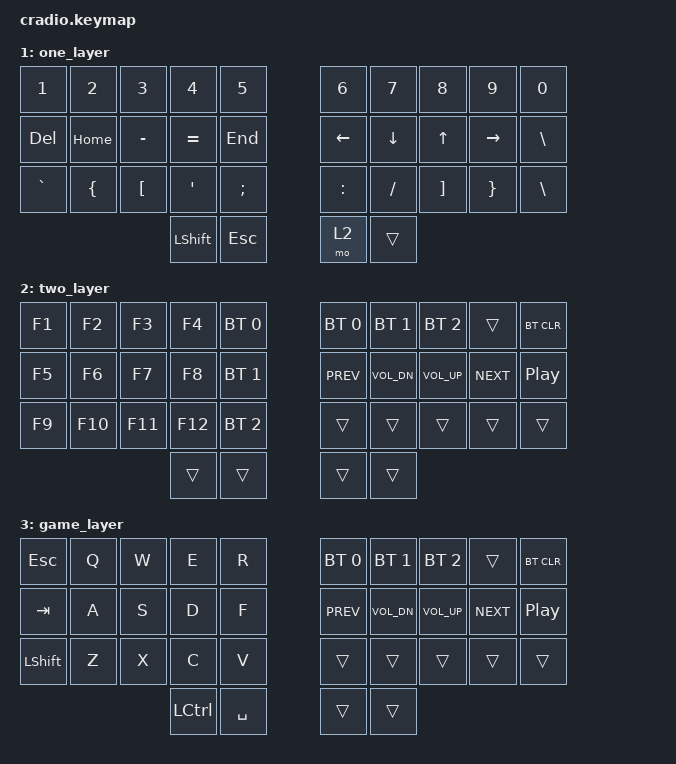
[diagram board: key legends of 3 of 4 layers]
// Copyright (c) 2022 The ZMK Contributors
// SPDX-License-Identifier: MIT

#include <behaviors.dtsi>
#include <dt-bindings/zmk/keys.h>
#include <dt-bindings/zmk/bt.h>

// Home row mods macro
#define HRML(k1,k2,k3) &ht LALT k1  &ht LCTRL k2  &ht LGUI k3
#define HRMR(k1,k2,k3) &ht RGUI k1  &ht RCTRL k2  &ht RALT k3
#define COMBO 60

/ {
    behaviors {
        ht: hold_tap {
            label = "hold_tap";
            compatible = "zmk,behavior-hold-tap";
            #binding-cells = <2>;
            flavor = "tap-preferred";
            tapping-term-ms = <220>;
            quick-tap-ms = <150>;
            require-prior-idle-ms = <100>;
            bindings = <&kp>, <&kp>;
        };
    };

    conditional_layers {
        compatible = "zmk,conditional-layers";
        tri_layer {
            if-layers = <1 2>;
            then-layer = <3>;
        };
    };
    combos {
        compatible = "zmk,combos";

        combo_del {
            timeout-ms = <COMBO>;
            key-positions = <17 18>;
            bindings = <&kp DEL>;
        };
        combo_bs_word{
            timeout-ms = <COMBO>;
            key-positions = <18 16 17>;
            bindings = <&kp LA(BSPC)>;
        };
        combo_bs{
            timeout-ms = <COMBO>;
            key-positions = <17 16>;
            bindings = <&kp BSPC>;
        };
        combo_esc {
            timeout-ms = <COMBO>;
            key-positions = <9 19>;
            bindings = <&kp ESC>;
        };

        combo_tab {
            timeout-ms = <COMBO>;
            key-positions = <12 13>;
            bindings = <&kp TAB>;
        };

        combo_lpar {
            timeout-ms = <COMBO>;
            key-positions = <2 12>;
            bindings = <&kp LPAR>;
        };
        combo_rpar {
            timeout-ms = <COMBO>;
            key-positions = <7 17>;
            bindings = <&kp RPAR>;
        };

        combo_lbkt {
            timeout-ms = <COMBO>;
            key-positions = <12 22>;
            bindings = <&kp LBKT>;
        };
        combo_rbkt {
            timeout-ms = <COMBO>;
            key-positions = <17 27>;
            bindings = <&kp RBKT>;
        };

    };
    
    keymap {
        compatible = "zmk,keymap";
        default_layer {
            bindings = <
        //╭──────────┬──────────┬──────────┬──────────┬──────────╮   ╭──────────┬──────────┬──────────┬──────────┬──────────╮
            &kp Q      &kp W      &kp E      &kp R      &kp T          &kp Y      &kp U      &kp I      &kp O      &kp P
        //├──────────┼──────────┼──────────┼──────────┼──────────┤   ├──────────┼──────────┼──────────┼──────────┼──────────┤
            &kp A        &kp S       &kp D       &kp F     &kp G          &kp H     &kp J      &kp  K        &kp L &kp ENTER
        //├──────────┼──────────┼──────────┼──────────┼──────────┤   ├──────────┼──────────┼──────────┼──────────┼──────────┤
            &kp Z     HRML( X,       C,       V)      &kp B          &kp N     HRMR( M,      COMMA,   DOT)      &kp SLASH
        //╰──────────┴──────────┴──────────┼──────────┼──────────┤   ├──────────┼──────────┼──────────┴──────────┴──────────╯
                                            &kp LGUI  &mo 1         &kp SPACE  &mt RSHFT ESC
        //                                 ╰──────────┴──────────╯   ╰──────────┴──────────╯
            >;
        };

        one_layer {
            bindings = <
        //╭──────────┬──────────┬──────────┬──────────┬──────────╮   ╭──────────┬──────────┬──────────┬──────────┬──────────╮
            &kp N1     &kp N2     &kp N3     &kp N4     &kp N5           &kp N6     &kp N7     &kp N8     &kp N9     &kp N0
        //├──────────┼──────────┼──────────┼──────────┼──────────┤   ├──────────┼──────────┼──────────┼──────────┼──────────┤
            &kp DEL    &kp HOME   &kp MINUS  &kp EQUAL  &kp END       &kp LEFT   &kp DOWN   &kp UP   &kp RIGHT   &kp BSLH
        //├──────────┼──────────┼──────────┼──────────┼──────────┤   ├──────────┼──────────┼──────────┼──────────┼──────────┤
           &kp GRAVE  &kp LBRC    &kp LBKT   &kp SQT    &kp SEMI       &kp COLON  &kp SLASH  &kp RBKT   &kp RBRC    &kp BSLH
        //╰──────────┴──────────┴──────────┼──────────┼──────────┤   ├──────────┼──────────┼──────────┴──────────┴──────────╯
                                             &kp LSHFT     &kp ESC        &mo 2    &trans
        //                                 ╰──────────┴──────────╯   ╰──────────┴──────────╯
            >;
        };

        two_layer {
            bindings = <
        //╭──────────┬──────────┬──────────┬──────────┬──────────╮   ╭──────────┬──────────┬──────────┬──────────┬──────────╮
        //│ RESET    │          │          │          │PROFILE 0 │   │          │          │          │          │          │
           &kp F1     &kp F2     &kp F3     &kp F4     &bt BT_SEL 0  &bt BT_SEL 0 &bt BT_SEL 1 &bt BT_SEL 2 &trans  &bt BT_CLR
        //├──────────┼──────────┼──────────┼──────────┼──────────┤   ├──────────┼──────────┼──────────┼──────────┼──────────┤
          &kp F5     &kp F6     &kp F7     &kp F8      &bt BT_SEL 1  &kp C_PREV &kp C_VOL_DN &kp C_VOL_UP &kp C_NEXT &kp C_PP
        //├──────────┼──────────┼──────────┼──────────┼──────────┤   ├──────────┼──────────┼──────────┼──────────┼──────────┤
            &kp F9     &kp F10    &kp F11    &kp F12   &bt BT_SEL 2    &trans     &trans     &trans     &trans     &trans
        //╰──────────┴──────────┴──────────┼──────────┼──────────┤   ├──────────┼──────────┼──────────┴──────────┴──────────╯
                                             &trans     &trans         &trans     &trans
        //                                 ╰──────────┴──────────╯   ╰──────────┴──────────╯
            >;
        };

        game_layer {
            bindings = <
        //╭──────────┬──────────┬──────────┬──────────┬──────────╮   ╭──────────┬──────────┬──────────┬──────────┬──────────╮
           &kp ESC     &kp Q     &kp W        &kp E       &kp R         &bt BT_SEL 0 &bt BT_SEL 1 &bt BT_SEL 2 &trans  &bt BT_CLR
        //├──────────┼──────────┼──────────┼──────────┼──────────┤   ├──────────┼──────────┼──────────┼──────────┼──────────┤
          &kp TAB      &kp A     &kp S      &kp D      &kp F   &kp C_PREV &kp C_VOL_DN &kp C_VOL_UP &kp C_NEXT &kp C_PP
        //├──────────┼──────────┼──────────┼──────────┼──────────┤   ├──────────┼──────────┼──────────┼──────────┼──────────┤
            &kp LSHFT   &kp Z    &kp X          &kp C    &kp V      &trans     &trans     &trans     &trans     &trans
        //╰──────────┴──────────┴──────────┼──────────┼──────────┤   ├──────────┼──────────┼──────────┴──────────┴──────────╯
                                             &kp LCTRL     &kp SPACE         &trans     &trans
        //                                 ╰──────────┴──────────╯   ╰──────────┴──────────╯
            >;
        };
    };
};
